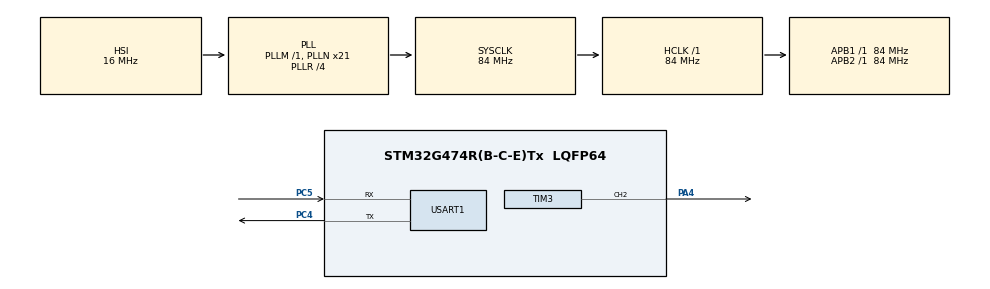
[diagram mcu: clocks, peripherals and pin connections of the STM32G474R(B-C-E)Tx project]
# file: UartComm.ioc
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Mcu.Family=STM32G4
Mcu.Name=STM32G474R(B-C-E)Tx
Mcu.Package=LQFP64
NVIC.PriorityGroup=NVIC_PRIORITYGROUP_4
NVIC.TIM3_IRQn=true\:0\:0\:false\:false\:true\:true\:true\:true
PA13.Mode=Serial_Wire
PA13.Signal=SYS_JTMS-SWDIO
PA14.Mode=Serial_Wire
PA14.Signal=SYS_JTCK-SWCLK
PA4.Signal=S_TIM3_CH2
PC4.Mode=Asynchronous
PC4.Signal=USART1_TX
PC5.Mode=Asynchronous
PC5.Signal=USART1_RX
PF0-OSC_IN.Mode=HSE-External-Oscillator
PF0-OSC_IN.Signal=RCC_OSC_IN
PF1-OSC_OUT.Mode=HSE-External-Oscillator
PF1-OSC_OUT.Signal=RCC_OSC_OUT
ProjectManager.HeapSize=0x200
ProjectManager.StackSize=0x400
ProjectManager.TargetToolchain=STM32CubeIDE
RCC.ADC12Freq_Value=84000000
RCC.ADC345Freq_Value=84000000
RCC.AHBFreq_Value=84000000
RCC.APB1Freq_Value=84000000
RCC.APB1TimFreq_Value=84000000
RCC.APB2Freq_Value=84000000
RCC.APB2TimFreq_Value=84000000
RCC.CortexFreq_Value=84000000
RCC.EXTERNAL_CLOCK_VALUE=12288000
RCC.HCLKFreq_Value=84000000
RCC.HSE_VALUE=8000000
RCC.HSI48_VALUE=48000000
RCC.HSI_VALUE=16000000
RCC.LSE_VALUE=32768
RCC.PLLN=21
RCC.PLLR=RCC_PLLR_DIV4
RCC.SYSCLKFreq_VALUE=84000000
RCC.SYSCLKSource=RCC_SYSCLKSOURCE_PLLCLK
RCC.USBFreq_Value=168000000
RCC.VCOOutputFreq_Value=336000000
SH.S_TIM3_CH2.0=TIM3_CH2,PWM Generation2 CH2
TIM3.Channel-PWM\ Generation2\ CH2=TIM_CHANNEL_2
TIM3.PeriodNoDither=1000-1
TIM3.Prescaler=1680-1
USART1.VirtualMode-Asynchronous=VM_ASYNC
VP_SYS_VS_DBSignals.Mode=DisableDeadBatterySignals
VP_TIM3_VS_ClockSourceINT.Mode=Internal
board=custom

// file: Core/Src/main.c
/* USER CODE BEGIN Header */
/**
  ******************************************************************************
  * @file           : main.c
  * @brief          : Main program body
  ******************************************************************************
  * @attention
  *
  * Copyright (c) 2024 STMicroelectronics.
  * All rights reserved.
  *
  * This software is licensed under terms that can be found in the LICENSE file
  * in the root directory of this software component.
  * If no LICENSE file comes with this software, it is provided AS-IS.
  *
  ******************************************************************************
  */
/* USER CODE END Header */
#include "main.h"

TIM_HandleTypeDef htim3;

UART_HandleTypeDef huart1;

void SystemClock_Config(void);
static void MX_GPIO_Init(void);
static void MX_TIM3_Init(void);
static void MX_USART1_UART_Init(void);

/* USER CODE BEGIN 0 */

uint8_t rx_data[4];
uint16_t value_1;
uint16_t value_2;
uint16_t value_3;
/* USER CODE END 0 */

int main(void)
{

  /* MCU Configuration--------------------------------------------------------*/

  /* Reset of all peripherals, Initializes the Flash interface and the Systick. */
  HAL_Init();

  /* Configure the system clock */
  SystemClock_Config();

  /* Initialize all configured peripherals */
  MX_GPIO_Init();
  MX_TIM3_Init();
  MX_USART1_UART_Init();
  /* USER CODE BEGIN 2 */
  HAL_TIM_PWM_Start(&htim3, TIM_CHANNEL_2);

  /* USER CODE END 2 */

  /* Infinite loop */
  while (1)
  {

    /* USER CODE BEGIN 3 */
	  value_1=((rx_data[0] -48)*100)+((rx_data[1]-48)*10)+(rx_data[2]-48);
	  value_2=((rx_data[0] -48)*10)+((rx_data[1]-48));
	  value_3=(rx_data[0] -48);
	  HAL_UART_Receive(&huart1,rx_data,sizeof(rx_data), 10);
	  if((rx_data[2]!='\n')&&(rx_data[1]!='\n'))
	  {
		  TIM3->CCR2=(value_1)*144/190;
	  }
	  else if((rx_data[2]=='\n')&&(rx_data[1]=='\n'))
	  {
		  TIM3->CCR2=(value_3)*144/190;
	  }
	  else if(rx_data[2]=='\n')
	  {
		 TIM3->CCR2=(value_2)*144/190;
	  }
	  HAL_Delay(10);
  }
  /* USER CODE END 3 */
}

void SystemClock_Config(void)
{
  RCC_OscInitTypeDef RCC_OscInitStruct = {0};
  RCC_ClkInitTypeDef RCC_ClkInitStruct = {0};

  /** Configure the main internal regulator output voltage
  */
  HAL_PWREx_ControlVoltageScaling(PWR_REGULATOR_VOLTAGE_SCALE1);

  /** Initializes the RCC Oscillators according to the specified parameters
  * in the RCC_OscInitTypeDef structure.
  */
  RCC_OscInitStruct.OscillatorType = RCC_OSCILLATORTYPE_HSI;
  RCC_OscInitStruct.HSIState = RCC_HSI_ON;
  RCC_OscInitStruct.HSICalibrationValue = RCC_HSICALIBRATION_DEFAULT;
  RCC_OscInitStruct.PLL.PLLState = RCC_PLL_ON;
  RCC_OscInitStruct.PLL.PLLSource = RCC_PLLSOURCE_HSI;
  RCC_OscInitStruct.PLL.PLLM = RCC_PLLM_DIV1;
  RCC_OscInitStruct.PLL.PLLN = 21;
  RCC_OscInitStruct.PLL.PLLP = RCC_PLLP_DIV2;
  RCC_OscInitStruct.PLL.PLLQ = RCC_PLLQ_DIV2;
  RCC_OscInitStruct.PLL.PLLR = RCC_PLLR_DIV4;
  if (HAL_RCC_OscConfig(&RCC_OscInitStruct) != HAL_OK)
  {
    Error_Handler();
  }

  /** Initializes the CPU, AHB and APB buses clocks
  */
  RCC_ClkInitStruct.ClockType = RCC_CLOCKTYPE_HCLK|RCC_CLOCKTYPE_SYSCLK
                              |RCC_CLOCKTYPE_PCLK1|RCC_CLOCKTYPE_PCLK2;
  RCC_ClkInitStruct.SYSCLKSource = RCC_SYSCLKSOURCE_PLLCLK;
  RCC_ClkInitStruct.AHBCLKDivider = RCC_SYSCLK_DIV1;
  RCC_ClkInitStruct.APB1CLKDivider = RCC_HCLK_DIV1;
  RCC_ClkInitStruct.APB2CLKDivider = RCC_HCLK_DIV1;

  if (HAL_RCC_ClockConfig(&RCC_ClkInitStruct, FLASH_LATENCY_2) != HAL_OK)
  {
    Error_Handler();
  }
}

static void MX_TIM3_Init(void)
{

  TIM_ClockConfigTypeDef sClockSourceConfig = {0};
  TIM_MasterConfigTypeDef sMasterConfig = {0};
  TIM_OC_InitTypeDef sConfigOC = {0};

  htim3.Instance = TIM3;
  htim3.Init.Prescaler = 1680-1;
  htim3.Init.CounterMode = TIM_COUNTERMODE_UP;
  htim3.Init.Period = 999;
  htim3.Init.ClockDivision = TIM_CLOCKDIVISION_DIV1;
  htim3.Init.AutoReloadPreload = TIM_AUTORELOAD_PRELOAD_DISABLE;
  if (HAL_TIM_Base_Init(&htim3) != HAL_OK)
  {
    Error_Handler();
  }
  sClockSourceConfig.ClockSource = TIM_CLOCKSOURCE_INTERNAL;
  if (HAL_TIM_ConfigClockSource(&htim3, &sClockSourceConfig) != HAL_OK)
  {
    Error_Handler();
  }
  if (HAL_TIM_PWM_Init(&htim3) != HAL_OK)
  {
    Error_Handler();
  }
  sMasterConfig.MasterOutputTrigger = TIM_TRGO_RESET;
  sMasterConfig.MasterSlaveMode = TIM_MASTERSLAVEMODE_DISABLE;
  if (HAL_TIMEx_MasterConfigSynchronization(&htim3, &sMasterConfig) != HAL_OK)
  {
    Error_Handler();
  }
  sConfigOC.OCMode = TIM_OCMODE_PWM1;
  sConfigOC.Pulse = 0;
  sConfigOC.OCPolarity = TIM_OCPOLARITY_HIGH;
  sConfigOC.OCFastMode = TIM_OCFAST_DISABLE;
  if (HAL_TIM_PWM_ConfigChannel(&htim3, &sConfigOC, TIM_CHANNEL_2) != HAL_OK)
  {
    Error_Handler();
  }
  HAL_TIM_MspPostInit(&htim3);

}

static void MX_USART1_UART_Init(void)
{

  huart1.Instance = USART1;
  huart1.Init.BaudRate = 115200;
  huart1.Init.WordLength = UART_WORDLENGTH_8B;
  huart1.Init.StopBits = UART_STOPBITS_1;
  huart1.Init.Parity = UART_PARITY_NONE;
  huart1.Init.Mode = UART_MODE_TX_RX;
  huart1.Init.HwFlowCtl = UART_HWCONTROL_NONE;
  huart1.Init.OverSampling = UART_OVERSAMPLING_16;
  huart1.Init.OneBitSampling = UART_ONE_BIT_SAMPLE_DISABLE;
  huart1.Init.ClockPrescaler = UART_PRESCALER_DIV1;
  huart1.AdvancedInit.AdvFeatureInit = UART_ADVFEATURE_NO_INIT;
  if (HAL_UART_Init(&huart1) != HAL_OK)
  {
    Error_Handler();
  }
  if (HAL_UARTEx_SetTxFifoThreshold(&huart1, UART_TXFIFO_THRESHOLD_1_8) != HAL_OK)
  {
    Error_Handler();
  }
  if (HAL_UARTEx_SetRxFifoThreshold(&huart1, UART_RXFIFO_THRESHOLD_1_8) != HAL_OK)
  {
    Error_Handler();
  }
  if (HAL_UARTEx_DisableFifoMode(&huart1) != HAL_OK)
  {
    Error_Handler();
  }

}

static void MX_GPIO_Init(void)
{

  /* GPIO Ports Clock Enable */
  __HAL_RCC_GPIOF_CLK_ENABLE();
  __HAL_RCC_GPIOA_CLK_ENABLE();
  __HAL_RCC_GPIOC_CLK_ENABLE();

}

void Error_Handler(void)
{
  __disable_irq();
  while (1)
  {
  }
}
